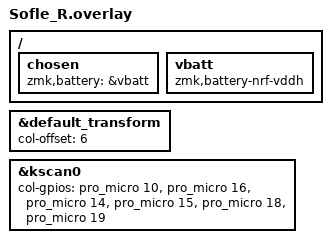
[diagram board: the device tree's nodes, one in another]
#include "Sofle.dtsi"

/* Right half is columns 6–11 in the 12-col transform */
&default_transform {
    col-offset = <6>;
};

/* Right-side matrix column GPIOs (mirrored order) */
&kscan0 {
    col-gpios
        = <&pro_micro 10 GPIO_ACTIVE_HIGH>
        , <&pro_micro 16 GPIO_ACTIVE_HIGH>
        , <&pro_micro 14 GPIO_ACTIVE_HIGH>
        , <&pro_micro 15 GPIO_ACTIVE_HIGH>
        , <&pro_micro 18 GPIO_ACTIVE_HIGH>
        , <&pro_micro 19 GPIO_ACTIVE_HIGH>
        ;
};

/* Enable right encoder if you use it (optional)
&right_encoder {
    status = "okay";
};
*/

/ {
    chosen {
        zmk,battery = &vbatt;
    };

    vbatt: vbatt {
        compatible = "zmk,battery-nrf-vddh";
    };
};
